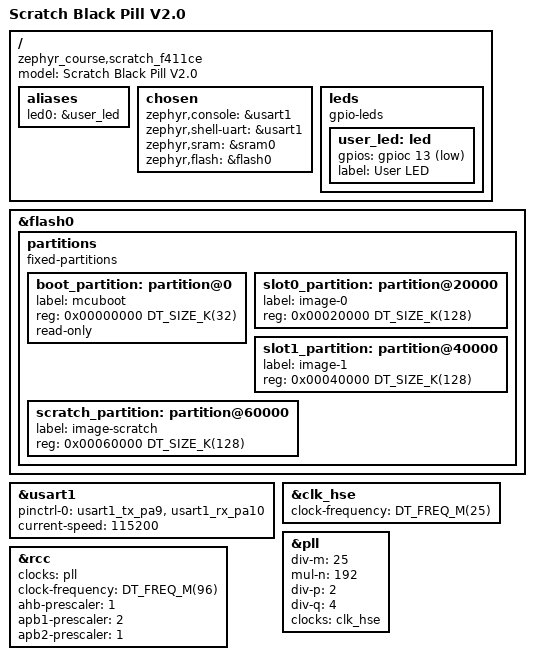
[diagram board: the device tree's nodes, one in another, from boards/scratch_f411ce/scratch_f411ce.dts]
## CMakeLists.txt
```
cmake_minimum_required(VERSION 3.20.0)

list(APPEND BOARD_ROOT ${CMAKE_CURRENT_SOURCE_DIR})
find_package(Zephyr REQUIRED)
project(my_zephyr_app)

target_sources(app PRIVATE src/main.cpp)

add_subdirectory(drivers/custom_sensor_led)
```

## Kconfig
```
config APP_HEARTBEAT_PERIOD_MS
    int "Heartbeat period [ms]"
    default 500
    range 100 2000

menuconfig LED_SUBSYSTEM
    bool "LED Subsystem"
    default y

if LED_SUBSYSTEM

    choice 
        prompt "Led blink sleep time"
        default BLINK_SLEEP_TIME_1000MS

    config BLINK_SLEEP_TIME_250MS
        bool "250ms (very fast)"

    config BLINK_SLEEP_TIME_500MS
        bool "500ms (fast)"

    config BLINK_SLEEP_TIME_1000MS
        bool "1s (medium)"

    config BLINK_SLEEP_TIME_2000MS
        bool "2s (slow)"
        
    endchoice

    menuconfig LED_ADVANCED
        bool "Advanced LED setting"

    if LED_ADVANCED

        config LED_BRIGHTNESS
            int "LED brightness (0-100)"
            range 0 100
            default 100

        config LED_FADE_MS
            int "LED fade duration (ms)"
            range 0 5000
            default 500

        menu "Expert settings"
            visible if LED_ADVANCED

            config LED_DEBUG
                bool "Enable LED debugging"

            config BLINK_PATTERN
                bool "Custom blink pattern"
            
        endmenu

    endif # LED_ADVANCED

endif # LED_SUBSYSTEM

source "Kconfig.zephyr"
rsource "drivers/custom_sensor_led/Kconfig"
```

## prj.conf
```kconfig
CONFIG_GPIO=y
CONFIG_LOG=y
CONFIG_SENSOR=y
CONFIG_CUSTOM_SENSOR_LED=y
CONFIG_SHELL=y
```

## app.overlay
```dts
&user_led {
    status = "disabled";
};

/ {
    aliases {
        // app-led = &user_led;
        sensor-led = &board_led;
    };

    board_led: board_led {
        compatible = "custom,sensor_led";
        gpios = <&gpioc 13 GPIO_ACTIVE_LOW>;
        status = "okay";
    };
};
```

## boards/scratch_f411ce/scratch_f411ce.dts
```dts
/dts-v1/;
#include <st/f4/stm32f411Xe.dtsi>
#include <st/f4/stm32f411c(c-e)ux-pinctrl.dtsi>

/ {
    model = "Scratch Black Pill V2.0";
	compatible = "zephyr_course,scratch_f411ce";

    aliases {
		led0 = &user_led;
	};

    chosen {
		zephyr,console = &usart1;
		zephyr,shell-uart = &usart1;
		zephyr,sram = &sram0;
		zephyr,flash = &flash0;
	};

    leds {
		compatible = "gpio-leds";

		user_led: led {
			gpios = <&gpioc 13 GPIO_ACTIVE_LOW>;
			label = "User LED";
		};
	};
};

&flash0 {
	partitions {
		compatible = "fixed-partitions";
		#address-cells = <1>;
		#size-cells = <1>;

		boot_partition: partition@0 {
			label = "mcuboot";
			reg = <0x00000000 DT_SIZE_K(32)>;
			read-only;
		};

		/*
		 * The flash starting at offset 0x00008000 and ending at
		 * offset 0x0001ffff (sectors 2 through 4) is reserved for
		 * use by the application.
		 */

		slot0_partition: partition@20000 {
			label = "image-0";
			reg = <0x00020000 DT_SIZE_K(128)>;
		};

		slot1_partition: partition@40000 {
			label = "image-1";
			reg = <0x00040000 DT_SIZE_K(128)>;
		};

		scratch_partition: partition@60000 {
			label = "image-scratch";
			reg = <0x00060000 DT_SIZE_K(128)>;
		};
	};
};

&usart1 {
	pinctrl-0 = <&usart1_tx_pa9 &usart1_rx_pa10>;
	pinctrl-names = "default";
	status = "okay";
	current-speed = <115200>;
};

&clk_hse {
	clock-frequency = <DT_FREQ_M(25)>;
	status = "okay";
};

&pll {
	div-m = <25>;
	mul-n = <192>;
	div-p = <2>;
	div-q = <4>;
	clocks = <&clk_hse>;
	status = "okay";
};

&rcc {
	clocks = <&pll>;
	clock-frequency = <DT_FREQ_M(96)>;
	ahb-prescaler = <1>;
	apb1-prescaler = <2>;
	apb2-prescaler = <1>;
};
```

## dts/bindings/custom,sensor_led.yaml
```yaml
description: LED sensor driver
compatible: "custom,sensor_led"
include: base.yaml

properties:
  gpios:
    type: phandle-array
    required: true
```

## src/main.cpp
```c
// #include <zephyr/drivers/gpio.h>
#include <zephyr/drivers/sensor.h>
#include <zephyr/kernel.h>
#include <zephyr/logging/log.h>
#include "custom_sensor_led.h"

/* The devicetree node identifier for the "app-led" alias. */
// #define LED_NODE DT_ALIAS(app_led)
#define LED_SENSOR_NODE DT_ALIAS(sensor_led)

// static const struct gpio_dt_spec led = GPIO_DT_SPEC_GET(LED_NODE, gpios);
static const struct device *custom_sensor_led = DEVICE_DT_GET(LED_SENSOR_NODE);

LOG_MODULE_REGISTER(main, LOG_LEVEL_INF);

int main(void)
{
    bool led_state = false;
    int32_t times_toggled;

    // if(!gpio_is_ready_dt(&led)) return 0;
    if(!device_is_ready(custom_sensor_led)) return 0;

    // if(gpio_pin_configure_dt(&led, GPIO_OUTPUT_ACTIVE) < 0) return 0;

    while(1) {
        // if(gpio_pin_toggle_dt(&led) < 0) return 0;
        if(led_state == false) {
            sensor_sample_fetch(custom_sensor_led);
            led_state = true;
        }
        else {
            sensor_channel_get(custom_sensor_led, SENSOR_CHAN_ALL, NULL);
            led_state = false;
        }

        times_toggled = led_toggled(custom_sensor_led, 0xFFFFFFFF);
        // led_state = !led_state;
        // LOG_INF("LED state: %s, toggled %d times", led_state ? "ON" : "OFF", times_toggled);
        k_msleep(CONFIG_APP_HEARTBEAT_PERIOD_MS);
    }
    return 0;
}
```
